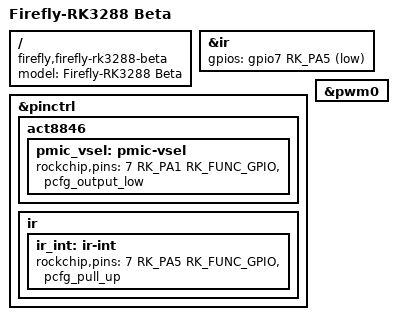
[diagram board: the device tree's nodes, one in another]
/dts-v1/;
#include "rk3288-firefly.dtsi"
/ {
	model = "Firefly-RK3288 Beta";
	compatible = "firefly,firefly-rk3288-beta", "rockchip,rk3288";
};
&ir {
	gpios = <&gpio7 RK_PA5 GPIO_ACTIVE_LOW>;
};
&pinctrl {
	act8846 {
		pmic_vsel: pmic-vsel {
			rockchip,pins = <7 RK_PA1 RK_FUNC_GPIO &pcfg_output_low>;
		};
	};
	ir {
		ir_int: ir-int {
			rockchip,pins = <7 RK_PA5 RK_FUNC_GPIO &pcfg_pull_up>;
		};
	};
};
&pwm0 {
	status = "okay";
};
